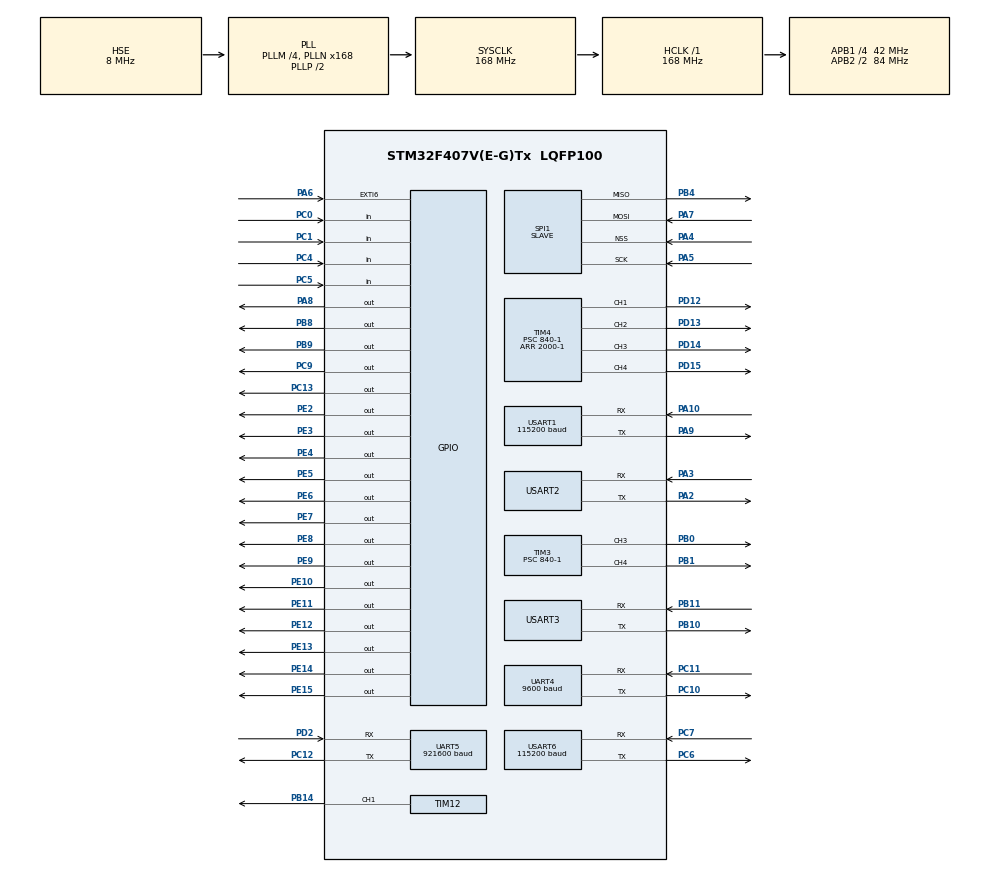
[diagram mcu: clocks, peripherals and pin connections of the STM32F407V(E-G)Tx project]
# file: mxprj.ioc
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Dma.Request0=UART4_RX
Dma.Request1=USART1_RX
Dma.Request2=UART5_RX
Dma.UART4_RX.0.Direction=DMA_PERIPH_TO_MEMORY
Dma.UART4_RX.0.FIFOMode=DMA_FIFOMODE_DISABLE
Dma.UART4_RX.0.Instance=DMA1_Stream2
Dma.UART4_RX.0.MemDataAlignment=DMA_MDATAALIGN_BYTE
Dma.UART4_RX.0.MemInc=DMA_MINC_ENABLE
Dma.UART4_RX.0.Mode=DMA_NORMAL
Dma.UART4_RX.0.PeriphDataAlignment=DMA_PDATAALIGN_BYTE
Dma.UART4_RX.0.PeriphInc=DMA_PINC_DISABLE
Dma.UART4_RX.0.Priority=DMA_PRIORITY_HIGH
Dma.UART5_RX.2.Direction=DMA_PERIPH_TO_MEMORY
Dma.UART5_RX.2.FIFOMode=DMA_FIFOMODE_DISABLE
Dma.UART5_RX.2.Instance=DMA1_Stream0
Dma.UART5_RX.2.MemDataAlignment=DMA_MDATAALIGN_BYTE
Dma.UART5_RX.2.MemInc=DMA_MINC_ENABLE
Dma.UART5_RX.2.Mode=DMA_CIRCULAR
Dma.UART5_RX.2.PeriphDataAlignment=DMA_PDATAALIGN_BYTE
Dma.UART5_RX.2.PeriphInc=DMA_PINC_DISABLE
Dma.UART5_RX.2.Priority=DMA_PRIORITY_LOW
Dma.USART1_RX.1.Direction=DMA_PERIPH_TO_MEMORY
Dma.USART1_RX.1.FIFOMode=DMA_FIFOMODE_DISABLE
Dma.USART1_RX.1.Instance=DMA2_Stream2
Dma.USART1_RX.1.MemDataAlignment=DMA_MDATAALIGN_BYTE
Dma.USART1_RX.1.MemInc=DMA_MINC_ENABLE
Dma.USART1_RX.1.Mode=DMA_NORMAL
Dma.USART1_RX.1.PeriphDataAlignment=DMA_PDATAALIGN_BYTE
Dma.USART1_RX.1.PeriphInc=DMA_PINC_DISABLE
Dma.USART1_RX.1.Priority=DMA_PRIORITY_LOW
Mcu.Family=STM32F4
Mcu.Name=STM32F407V(E-G)Tx
Mcu.Package=LQFP100
NVIC.DMA1_Stream0_IRQn=true\:0\:0\:false\:false\:true\:false\:true\:true
NVIC.DMA1_Stream2_IRQn=true\:0\:0\:false\:false\:true\:false\:true\:true
NVIC.DMA2_Stream2_IRQn=true\:1\:0\:true\:false\:true\:false\:true\:true
NVIC.PriorityGroup=NVIC_PRIORITYGROUP_4
NVIC.TIM6_DAC_IRQn=true\:1\:0\:true\:false\:true\:true\:true\:true
NVIC.TIM7_IRQn=true\:1\:0\:true\:false\:true\:true\:true\:true
NVIC.TIM8_UP_TIM13_IRQn=true\:2\:0\:true\:false\:true\:true\:true\:true
NVIC.UART4_IRQn=true\:1\:0\:true\:false\:true\:true\:true\:true
NVIC.UART5_IRQn=true\:1\:0\:true\:false\:true\:true\:true\:true
NVIC.USART1_IRQn=true\:2\:0\:true\:false\:true\:true\:true\:true
NVIC.USART3_IRQn=true\:0\:0\:false\:false\:true\:true\:true\:true
NVIC.USART6_IRQn=true\:0\:0\:false\:false\:true\:true\:true\:true
PA10.Mode=Asynchronous
PA10.Signal=USART1_RX
PA13.Mode=Serial_Wire
PA13.Signal=SYS_JTMS-SWDIO
PA14.Mode=Serial_Wire
PA14.Signal=SYS_JTCK-SWCLK
PA2.Mode=Asynchronous
PA2.Signal=USART2_TX
PA3.Mode=Asynchronous
PA3.Signal=USART2_RX
PA4.Mode=NSS_Signal_Hard_Input
PA4.Signal=SPI1_NSS
PA5.Mode=Full_Duplex_Slave
PA5.Signal=SPI1_SCK
PA6.Signal=GPXTI6
PA7.Mode=Full_Duplex_Slave
PA7.Signal=SPI1_MOSI
PA8.Signal=GPIO_Output
PA9.Mode=Asynchronous
PA9.Signal=USART1_TX
PB0.Signal=S_TIM3_CH3
PB1.Signal=S_TIM3_CH4
PB10.Mode=Asynchronous
PB10.Signal=USART3_TX
PB11.Mode=Asynchronous
PB11.Signal=USART3_RX
PB14.Signal=S_TIM12_CH1
PB4.Mode=Full_Duplex_Slave
PB4.Signal=SPI1_MISO
PB8.Signal=GPIO_Output
PB9.Signal=GPIO_Output
PC0.GPIO_PuPd=GPIO_PULLDOWN
PC0.Signal=GPIO_Input
PC1.GPIO_PuPd=GPIO_PULLDOWN
PC1.Signal=GPIO_Input
PC10.Mode=Asynchronous
PC10.Signal=UART4_TX
PC11.Mode=Asynchronous
PC11.Signal=UART4_RX
PC12.Mode=Asynchronous
PC12.Signal=UART5_TX
PC13-ANTI_TAMP.Signal=GPIO_Output
PC14-OSC32_IN.Mode=LSE-External-Oscillator
PC14-OSC32_IN.Signal=RCC_OSC32_IN
PC15-OSC32_OUT.Mode=LSE-External-Oscillator
PC15-OSC32_OUT.Signal=RCC_OSC32_OUT
PC4.GPIO_PuPd=GPIO_PULLDOWN
PC4.Signal=GPIO_Input
PC5.GPIO_PuPd=GPIO_PULLDOWN
PC5.Signal=GPIO_Input
PC6.Mode=Asynchronous
PC6.Signal=USART6_TX
PC7.Mode=Asynchronous
PC7.Signal=USART6_RX
PC9.Signal=GPIO_Output
PD12.Signal=S_TIM4_CH1
PD13.Signal=S_TIM4_CH2
PD14.Signal=S_TIM4_CH3
PD15.Signal=S_TIM4_CH4
PD2.Mode=Asynchronous
PD2.Signal=UART5_RX
PE10.Signal=GPIO_Output
PE11.Signal=GPIO_Output
PE12.Signal=GPIO_Output
PE13.Signal=GPIO_Output
PE14.Signal=GPIO_Output
PE15.Signal=GPIO_Output
PE2.Signal=GPIO_Output
PE3.Signal=GPIO_Output
PE4.Signal=GPIO_Output
PE5.Signal=GPIO_Output
PE6.Signal=GPIO_Output
PE7.Signal=GPIO_Output
PE8.Signal=GPIO_Output
PE9.Signal=GPIO_Output
PH0-OSC_IN.Mode=HSE-External-Oscillator
PH0-OSC_IN.Signal=RCC_OSC_IN
PH1-OSC_OUT.Mode=HSE-External-Oscillator
PH1-OSC_OUT.Signal=RCC_OSC_OUT
ProjectManager.HeapSize=0x200
ProjectManager.StackSize=0x10000
ProjectManager.TargetToolchain=MDK-ARM V5.32
RCC.48MHZClocksFreq_Value=84000000
RCC.AHBFreq_Value=168000000
RCC.APB1CLKDivider=RCC_HCLK_DIV4
RCC.APB1Freq_Value=42000000
RCC.APB1TimFreq_Value=84000000
RCC.APB2CLKDivider=RCC_HCLK_DIV2
RCC.APB2Freq_Value=84000000
RCC.APB2TimFreq_Value=168000000
RCC.CortexFreq_Value=168000000
RCC.HCLKFreq_Value=168000000
RCC.HSE_VALUE=8000000
RCC.HSI_VALUE=16000000
RCC.PLLM=4
RCC.PLLN=168
RCC.PLLSourceVirtual=RCC_PLLSOURCE_HSE
RCC.SYSCLKFreq_VALUE=168000000
RCC.SYSCLKSource=RCC_SYSCLKSOURCE_PLLCLK
RCC.VCOOutputFreq_Value=336000000
SH.S_TIM12_CH1.0=TIM12_CH1,PWM Generation1 CH1
SH.S_TIM3_CH3.0=TIM3_CH3,PWM Generation3 CH3
SH.S_TIM3_CH4.0=TIM3_CH4,PWM Generation4 CH4
SH.S_TIM4_CH1.0=TIM4_CH1,PWM Generation1 CH1
SH.S_TIM4_CH2.0=TIM4_CH2,PWM Generation2 CH2
SH.S_TIM4_CH3.0=TIM4_CH3,PWM Generation3 CH3
SH.S_TIM4_CH4.0=TIM4_CH4,PWM Generation4 CH4
SPI1.Direction=SPI_DIRECTION_2LINES
SPI1.Mode=SPI_MODE_SLAVE
SPI1.VirtualNSS=VM_NSSHARD
SPI1.VirtualType=VM_SLAVE
TIM12.Channel-PWM\ Generation1\ CH1=TIM_CHANNEL_1
TIM12.Period=2000-1
TIM12.Prescaler=840-1
TIM13.Period=2500-1
TIM13.Prescaler=16800-1
TIM3.Channel-PWM\ Generation3\ CH3=TIM_CHANNEL_3
TIM3.Channel-PWM\ Generation4\ CH4=TIM_CHANNEL_4
TIM3.Period=2000-1
TIM3.Prescaler=840-1
TIM4.Channel-PWM\ Generation1\ CH1=TIM_CHANNEL_1
TIM4.Channel-PWM\ Generation2\ CH2=TIM_CHANNEL_2
TIM4.Channel-PWM\ Generation3\ CH3=TIM_CHANNEL_3
TIM4.Channel-PWM\ Generation4\ CH4=TIM_CHANNEL_4
TIM4.Period=2000-1
TIM4.Prescaler=840-1
TIM6.AutoReloadPreload=TIM_AUTORELOAD_PRELOAD_DISABLE
TIM6.Period=1000-1
TIM6.Prescaler=84-1
TIM7.Period=5-1
TIM7.Prescaler=84-1
UART4.BaudRate=9600
UART4.VirtualMode=Asynchronous
UART5.BaudRate=921600
UART5.VirtualMode=Asynchronous
USART1.BaudRate=115200
USART1.VirtualMode=VM_ASYNC
USART2.VirtualMode=VM_ASYNC
USART3.VirtualMode=VM_ASYNC
USART6.BaudRate=115200
USART6.VirtualMode=VM_ASYNC
VP_TIM13_VS_ClockSourceINT.Mode=Enable_Timer
VP_TIM6_VS_ClockSourceINT.Mode=Enable_Timer
VP_TIM7_VS_ClockSourceINT.Mode=Enable_Timer
board=custom

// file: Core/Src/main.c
/* USER CODE BEGIN Header */
/**
  ******************************************************************************
  * @file           : main.c
  * @brief          : Main program body
  ******************************************************************************
  * @attention
  *
  * Copyright (c) 2023 STMicroelectronics.
  * All rights reserved.
  *
  * This software is licensed under terms that can be found in the LICENSE file
  * in the root directory of this software component.
  * If no LICENSE file comes with this software, it is provided AS-IS.
  *
  ******************************************************************************
  */
/* USER CODE END Header */
#include "main.h"
#include "spi.h"
#include "tim.h"
#include "usart.h"
#include "gpio.h"

/* USER CODE BEGIN Includes */
#include "MainInteract.h"
/* USER CODE END Includes */

void SystemClock_Config(void);

int main(void)
{

  /* MCU Configuration--------------------------------------------------------*/

  /* Reset of all peripherals, Initializes the Flash interface and the Systick. */
  HAL_Init();

  /* Configure the system clock */
  SystemClock_Config();

  /* Initialize all configured peripherals */
  MX_GPIO_Init();
  MX_SPI1_Init();
  MX_TIM3_Init();
  MX_TIM4_Init();
  MX_UART4_Init();
  MX_UART5_Init();
  MX_USART1_UART_Init();
  MX_USART2_UART_Init();
  MX_USART3_UART_Init();
  MX_USART6_UART_Init();
  MX_TIM12_Init();
  MX_TIM6_Init();
  MX_TIM13_Init();
  MX_TIM7_Init();
  /* USER CODE BEGIN 2 */
  //HAL_TIM_Base_Start_IT(&htim13);
   Test_Mod();
  // Full_Step();
  /* USER CODE END 2 */

  /* Infinite loop */
  while (1)
  {

  }
}

void SystemClock_Config(void)
{
  RCC_OscInitTypeDef RCC_OscInitStruct = {0};
  RCC_ClkInitTypeDef RCC_ClkInitStruct = {0};

  /** Configure the main internal regulator output voltage
  */
  __HAL_RCC_PWR_CLK_ENABLE();
  __HAL_PWR_VOLTAGESCALING_CONFIG(PWR_REGULATOR_VOLTAGE_SCALE1);

  /** Initializes the RCC Oscillators according to the specified parameters
  * in the RCC_OscInitTypeDef structure.
  */
  RCC_OscInitStruct.OscillatorType = RCC_OSCILLATORTYPE_HSE;
  RCC_OscInitStruct.HSEState = RCC_HSE_ON;
  RCC_OscInitStruct.PLL.PLLState = RCC_PLL_ON;
  RCC_OscInitStruct.PLL.PLLSource = RCC_PLLSOURCE_HSE;
  RCC_OscInitStruct.PLL.PLLM = 4;
  RCC_OscInitStruct.PLL.PLLN = 168;
  RCC_OscInitStruct.PLL.PLLP = RCC_PLLP_DIV2;
  RCC_OscInitStruct.PLL.PLLQ = 4;
  if (HAL_RCC_OscConfig(&RCC_OscInitStruct) != HAL_OK)
  {
    Error_Handler();
  }

  /** Initializes the CPU, AHB and APB buses clocks
  */
  RCC_ClkInitStruct.ClockType = RCC_CLOCKTYPE_HCLK|RCC_CLOCKTYPE_SYSCLK
                              |RCC_CLOCKTYPE_PCLK1|RCC_CLOCKTYPE_PCLK2;
  RCC_ClkInitStruct.SYSCLKSource = RCC_SYSCLKSOURCE_PLLCLK;
  RCC_ClkInitStruct.AHBCLKDivider = RCC_SYSCLK_DIV1;
  RCC_ClkInitStruct.APB1CLKDivider = RCC_HCLK_DIV4;
  RCC_ClkInitStruct.APB2CLKDivider = RCC_HCLK_DIV2;

  if (HAL_RCC_ClockConfig(&RCC_ClkInitStruct, FLASH_LATENCY_5) != HAL_OK)
  {
    Error_Handler();
  }
}

void Error_Handler(void)
{
  __disable_irq();
  while (1)
  {
  }
}
